# ESP32-H2 register map
Vendor: ESPRESSIF SYSTEMS (SHANGHAI) CO., LTD.; Series: ESP32 H-Series; File version: 12
CPU: RV32IMAC r0p0, little endian, no MPU, no FPU, 0 interrupt priority bits
Address unit: 32 bits
Registers are 32-bit, read-write, reset 0x0 unless marked. A register's access mark holds for its fields unless they carry their own. Offsets are from the block's base; [hi:lo] are bit positions; {n}, {i} and the like mark numbered series.

## MEM_MONITOR — MEM_MONITOR Peripheral
Base 0x60092000
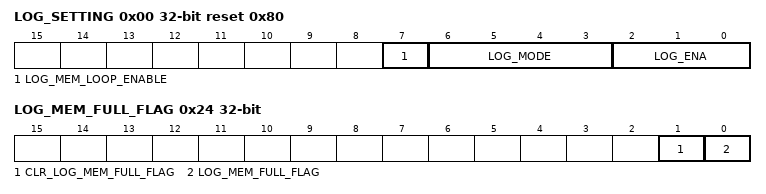
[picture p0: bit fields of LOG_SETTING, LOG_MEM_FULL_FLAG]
0x00 LOG_SETTING reset 0x80 — log config regsiter
  [7] LOG_MEM_LOOP_ENABLE — Set 1 enable mem_loop, it will loop write at the range of MEM_START and MEM_END
  [6:3] LOG_MODE — This field must be onehot. 4'b0001 : WR monitor, 4'b0010: WORD monitor, 4'b0100: HALFWORD monitor, 4'b1000: BYTE monitor.
  [2:0] LOG_ENA — enable bus log. BIT0: hp-cpu, BIT1: lp-cpu, BIT2: DMA.823 don't support lp-cpu
0x04 LOG_CHECK_DATA — check data regsiter
  [31:0] LOG_CHECK_DATA — The special check data, when write this special data, it will trigger logging.
0x08 LOG_DATA_MASK — check data mask register
  [3:0] LOG_DATA_MASK — byte mask enable, BIT0 mask the first byte of MEM_MONITOR_LOG_CHECK_DATA, and BIT1 mask second byte, and so on.
0x0C LOG_MIN — log boundary regsiter
  [31:0] LOG_MIN — the min address of log range
0x10 LOG_MAX — log boundary regsiter
  [31:0] LOG_MAX — the max address of log range
0x14 LOG_MEM_START — log message store range register
  [31:0] LOG_MEM_START — the start address of writing logging message
0x18 LOG_MEM_END — log message store range register
  [31:0] LOG_MEM_END — the end address of writing logging message
0x1C LOG_MEM_CURRENT_ADDR ro — current writing address.
  [31:0] LOG_MEM_CURRENT_ADDR — means next writing address
0x20 LOG_MEM_ADDR_UPDATE wo — writing address update
  [0] LOG_MEM_ADDR_UPDATE — Set 1 to updata MEM_MONITOR_LOG_MEM_CURRENT_ADDR, when set 1, MEM_MONITOR_LOG_MEM_CURRENT_ADDR will update to MEM_MONITOR_LOG_MEM_START
0x24 LOG_MEM_FULL_FLAG access per field — full flag status register
  [1] CLR_LOG_MEM_FULL_FLAG wo — Set 1 to clr MEM_MONITOR_LOG_MEM_FULL_FLAG
  [0] LOG_MEM_FULL_FLAG ro — 1 means memory write loop at least one time at the range of MEM_START and MEM_END
0x28 CLOCK_GATE — clock gate force on register
  [0] CLK_EN — Set 1 to force on the clk of mem_monitor register
0x3FC DATE — version register

## MODEM_LPCON — MODEM_LPCON Peripheral
Base 0x600AD000
0x00 TEST_CONF
  [0] CLK_EN
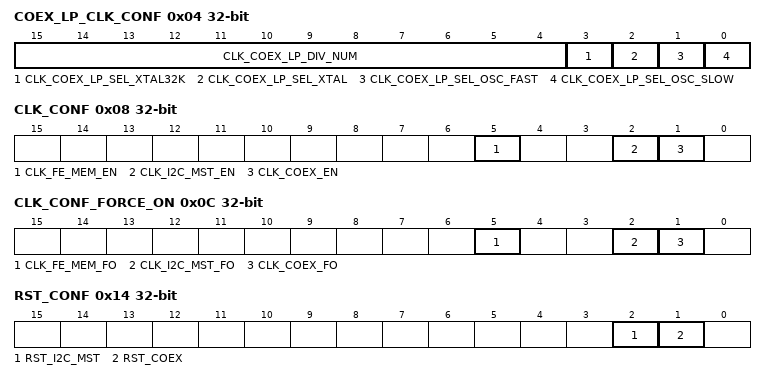
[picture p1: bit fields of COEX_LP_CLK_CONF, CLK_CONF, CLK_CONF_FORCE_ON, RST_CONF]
0x04 COEX_LP_CLK_CONF
  [15:4] CLK_COEX_LP_DIV_NUM, [3] CLK_COEX_LP_SEL_XTAL32K, [2] CLK_COEX_LP_SEL_XTAL, [1] CLK_COEX_LP_SEL_OSC_FAST, [0] CLK_COEX_LP_SEL_OSC_SLOW
0x08 CLK_CONF
  [5] CLK_FE_MEM_EN, [2] CLK_I2C_MST_EN, [1] CLK_COEX_EN
0x0C CLK_CONF_FORCE_ON
  [5] CLK_FE_MEM_FO, [2] CLK_I2C_MST_FO, [1] CLK_COEX_FO
0x10 TICK_CONF reset 0x1F
  [5:0] PWR_TICK_TARGET
0x14 RST_CONF wo
  [2] RST_I2C_MST, [1] RST_COEX
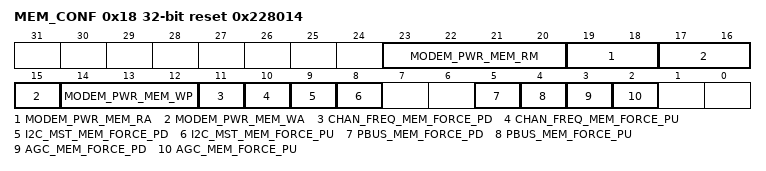
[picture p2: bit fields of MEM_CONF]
0x18 MEM_CONF reset 0x228014
  [23:20] MODEM_PWR_MEM_RM, [19:18] MODEM_PWR_MEM_RA, [17:15] MODEM_PWR_MEM_WA, [14:12] MODEM_PWR_MEM_WP, [11] CHAN_FREQ_MEM_FORCE_PD, [10] CHAN_FREQ_MEM_FORCE_PU, [9] I2C_MST_MEM_FORCE_PD, [8] I2C_MST_MEM_FORCE_PU, [5] PBUS_MEM_FORCE_PD, [4] PBUS_MEM_FORCE_PU, [3] AGC_MEM_FORCE_PD, [2] AGC_MEM_FORCE_PU
0x1C DATE — Version control register

## I2C_ANA_MST — I2C_ANA_MST Peripheral
Base 0x600AD800
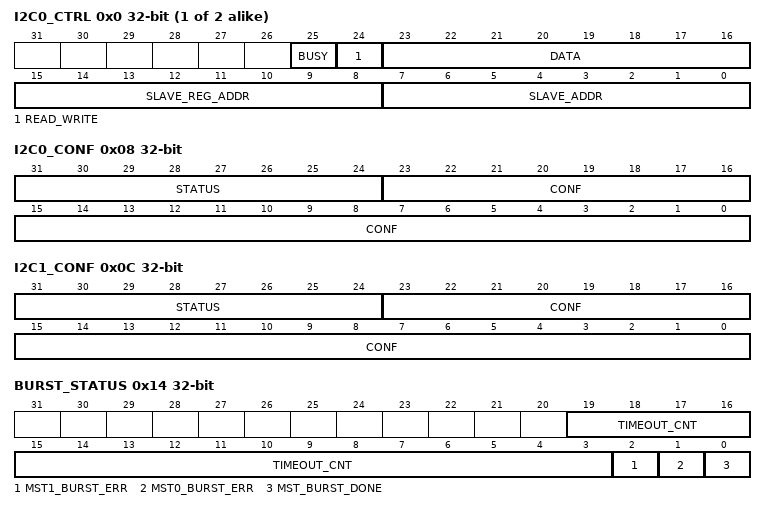
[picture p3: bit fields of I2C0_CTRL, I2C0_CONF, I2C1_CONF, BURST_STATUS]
{0x0+4i} I2C{i}_CTRL (i=0..1) — I2C{i}_CTRL register
  [25] BUSY ro — Represents whether I2C0 is currently transferring data
  [24] READ_WRITE — Configures the read/write operation
  [23:16] DATA — Configures the transmitted data
  [15:8] SLAVE_REG_ADDR — Configures the slave register address
  [7:0] SLAVE_ADDR — Configures the slave address
0x08 I2C0_CONF
  [31:24] STATUS ro — ?
  [23:0] CONF — ?
0x0C I2C1_CONF
  [31:24] STATUS ro — ?
  [23:0] CONF — ?
0x10 BURST_CONF
  [31:0] BURST_CTRL — ?
0x14 BURST_STATUS
  [19:3] TIMEOUT_CNT ro — ?
  [2] MST1_BURST_ERR ro — ?
  [1] MST0_BURST_ERR ro — ?
  [0] MST_BURST_DONE ro — ?
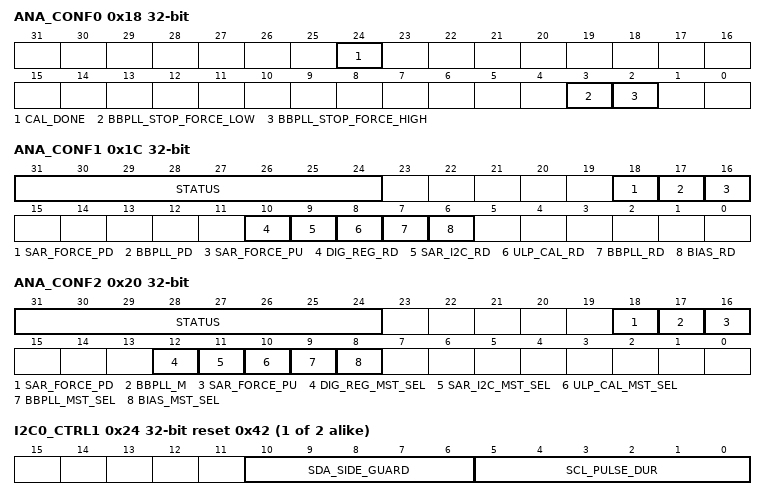
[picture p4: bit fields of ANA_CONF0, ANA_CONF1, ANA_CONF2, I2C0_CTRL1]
0x18 ANA_CONF0
  [24] CAL_DONE ro — BBPLL calibration done
  [3] BBPLL_STOP_FORCE_LOW — ?
  [2] BBPLL_STOP_FORCE_HIGH — ?
0x1C ANA_CONF1
  [31:24] STATUS ro — ?
  [18] SAR_FORCE_PD — ?
  [17] BBPLL_PD — Clear to enable BBPLL
  [16] SAR_FORCE_PU — ?
  [10] DIG_REG_RD — Clear to select
  [9] SAR_I2C_RD — Clear to select
  [8] ULP_CAL_RD — Clear to select
  [7] BBPLL_RD — Clear to select
  [6] BIAS_RD — Clear to select
0x20 ANA_CONF2
  [31:24] STATUS ro — ?
  [18] SAR_FORCE_PD — ?
  [17] BBPLL_M — Clear to enable BBPLL
  [16] SAR_FORCE_PU — ?
  [12] DIG_REG_MST_SEL — Configures which I2C master the following analog modules uses. If the corresponding bit is set to 1, I2C0 master is used for communication; if set to 0, I2C1 master is used.
  [11] SAR_I2C_MST_SEL — Configures which I2C master the following analog modules uses. If the corresponding bit is set to 1, I2C0 master is used for communication; if set to 0, I2C1 master is used.
  [10] ULP_CAL_MST_SEL — Configures which I2C master the following analog modules uses. If the corresponding bit is set to 1, I2C0 master is used for communication; if set to 0, I2C1 master is used.
  [9] BBPLL_MST_SEL — Configures which I2C master the following analog modules uses. If the corresponding bit is set to 1, I2C0 master is used for communication; if set to 0, I2C1 master is used.
  [8] BIAS_MST_SEL — Configures which I2C master the following analog modules uses. If the corresponding bit is set to 1, I2C0 master is used for communication; if set to 0, I2C1 master is used.
{0x24+4i} I2C{i}_CTRL1 (i=0..1) reset 0x42 — I2C{i}_CTRL1 register
  [10:6] SDA_SIDE_GUARD — Configures the duration of the low-level period of the SCL driven by I2C0
  [5:0] SCL_PULSE_DUR — Configures the duration of the high-level period of the SCL driven by I2C0
0x34 DATE
